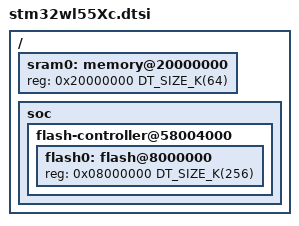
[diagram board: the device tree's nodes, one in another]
/*
 * Copyright (c) 2020 STMicroelectronics
 *
 * SPDX-License-Identifier: Apache-2.0
 */
#include <st/wl/stm32wl55.dtsi>

/ {
	sram0: memory@20000000 {
		reg = <0x20000000 DT_SIZE_K(64)>;
	};

	soc {
		flash-controller@58004000 {
			flash0: flash@8000000 {
				reg = <0x08000000 DT_SIZE_K(256)>;
				ranges = <0x0 0x8000000 DT_SIZE_K(256)>;
				#address-cells = <1>;
				#size-cells = <1>;
			};
		};
	};
};
